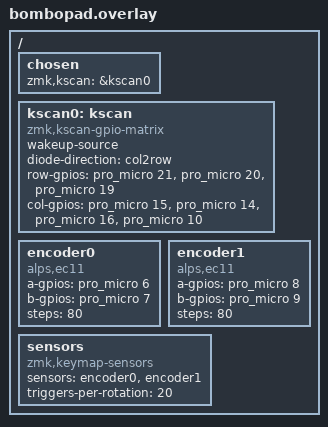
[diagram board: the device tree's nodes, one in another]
#include <dt-bindings/zmk/matrix_transform.h>

/ {
    chosen {
        zmk,kscan = &kscan0;
    };

    kscan0: kscan {
        compatible = "zmk,kscan-gpio-matrix";
        wakeup-source;

        diode-direction = "col2row";

         row-gpios
            = <&pro_micro 21 (GPIO_ACTIVE_HIGH | GPIO_PULL_DOWN)>
            , <&pro_micro 20 (GPIO_ACTIVE_HIGH | GPIO_PULL_DOWN)>
            , <&pro_micro 19 (GPIO_ACTIVE_HIGH | GPIO_PULL_DOWN)>
            ;

        col-gpios
            = <&pro_micro 15 GPIO_ACTIVE_HIGH>
            , <&pro_micro 14 GPIO_ACTIVE_HIGH>
            , <&pro_micro 16 GPIO_ACTIVE_HIGH>
            , <&pro_micro 10 GPIO_ACTIVE_HIGH>
            ;
    };
    
    encoder0: encoder0 {
        compatible = "alps,ec11";
        a-gpios = <&pro_micro 6 (GPIO_ACTIVE_HIGH | GPIO_PULL_UP)>;
        b-gpios = <&pro_micro 7 (GPIO_ACTIVE_HIGH | GPIO_PULL_UP)>;
        steps = <80>;
        status = "okay";
    };

    encoder1: encoder1 {
        compatible = "alps,ec11";
        a-gpios = <&pro_micro 8 (GPIO_ACTIVE_HIGH | GPIO_PULL_UP)>;
        b-gpios = <&pro_micro 9 (GPIO_ACTIVE_HIGH | GPIO_PULL_UP)>;
        steps = <80>;
        status = "okay";
    };

    sensors: sensors {
        compatible = "zmk,keymap-sensors";
        sensors = <&encoder0 &encoder1>;
        triggers-per-rotation = <20>;
    };
};
